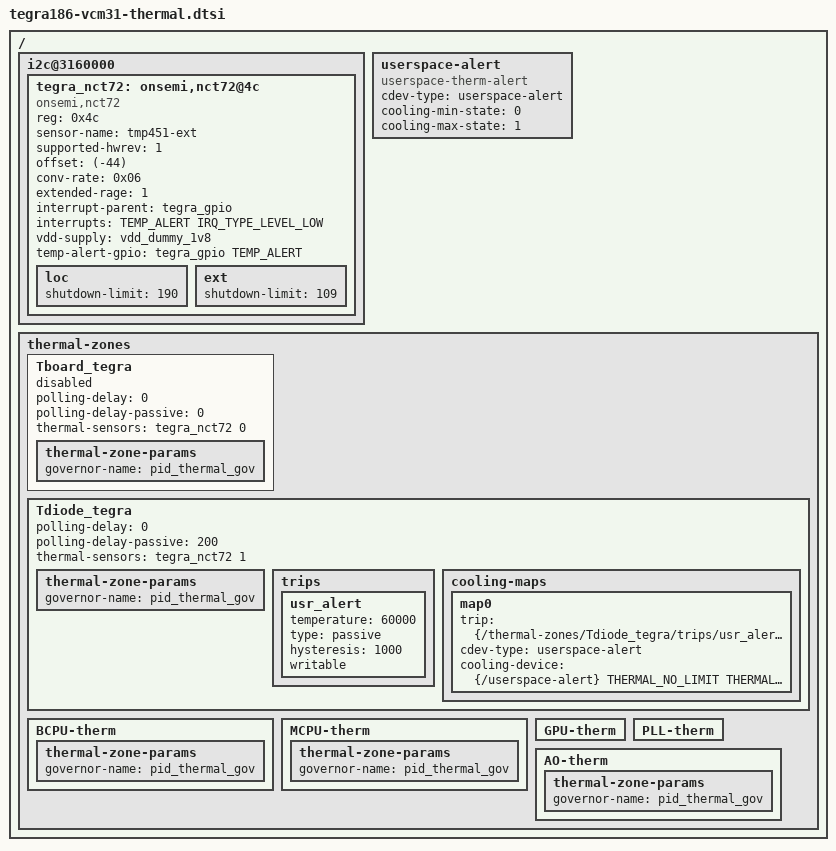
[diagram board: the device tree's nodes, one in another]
/*
 * Copyright (c) 2015-2017, NVIDIA CORPORATION. All rights reserved.
 *
 * This program is free software; you can redistribute it and/or modify it
 * under the terms and conditions of the GNU General Public License,
 * version 2, as published by the Free Software Foundation.
 *
 * This program is distributed in the hope it will be useful, but WITHOUT
 * ANY WARRANTY; without even the implied warranty of MERCHANTABILITY or
 * FITNESS FOR A PARTICULAR PURPOSE.  See the GNU General Public License for
 * more details.
 *
 * You should have received a copy of the GNU General Public License
 * along with this program.  If not, see <http://www.gnu.org/licenses/>.
 */

#include <dt-bindings/interrupt-controller/arm-gic.h>
#include <dt-bindings/gpio/tegra-gpio.h>
#include <dt-bindings/thermal/thermal.h>

/* THERMAL gpio definitions */
#define TEMP_ALERT		TEGRA_GPIO(V, 0)

/ {
	i2c@3160000 {
		tegra_nct72: onsemi,nct72@4c {
			#thermal-sensor-cells = <1>;
			compatible = "onsemi,nct72";
			reg = <0x4c>;
			sensor-name = "tmp451-ext";
			supported-hwrev = <1>;
			offset = <(-44)>;
			conv-rate = <0x06>;
			extended-rage = <1>;
			interrupt-parent = <&tegra_gpio>;
			interrupts = <TEMP_ALERT IRQ_TYPE_LEVEL_LOW>;
			vdd-supply = <&vdd_dummy_1v8>;
			temp-alert-gpio = <&tegra_gpio TEMP_ALERT 0>;
			loc {
				/* set to maximum for not having local  shutdown */
				shutdown-limit = <190>;
			};
			ext {
				shutdown-limit = <109>;
			};
		};
	};

	userspace-alert {
		compatible = "userspace-therm-alert";
		cdev-type = "userspace-alert";
		cooling-min-state = <0>;
		cooling-max-state = <1>;
		#cooling-cells = <2>;
	};


	thermal-zones {
		Tboard_tegra {
			status = "disabled";
			polling-delay = <0>;
			polling-delay-passive = <0>;
			thermal-sensors = <&tegra_nct72 0>;

			thermal-zone-params {
				governor-name = "pid_thermal_gov";
			};

		};

		Tdiode_tegra {
			status = "okay";
			polling-delay = <0>;
			polling-delay-passive = <200>;
			thermal-sensors = <&tegra_nct72 1>;

			thermal-zone-params {
				governor-name = "pid_thermal_gov";
			};

			trips {
				usr_alert {
					temperature = <60000>;
					type = "passive";
					hysteresis = <1000>;
					writable;
				};
			};

			cooling-maps {
				map0 {
					trip = <&{/thermal-zones/Tdiode_tegra/trips/usr_alert}>;
					cdev-type = "userspace-alert";
					cooling-device = <&{/userspace-alert} THERMAL_NO_LIMIT THERMAL_NO_LIMIT>;
				};
			};
		};

		BCPU-therm {
			status = "okay";

			thermal-zone-params {
				governor-name = "pid_thermal_gov";
			};
		};

		MCPU-therm {
			status = "okay";

			thermal-zone-params {
				governor-name = "pid_thermal_gov";
			};
		};

		GPU-therm {
			status = "okay";
		};

		PLL-therm {
			status = "okay";
		};

		AO-therm {
			status = "okay";
			thermal-zone-params {
				governor-name = "pid_thermal_gov";
			};

		};
	};
};
